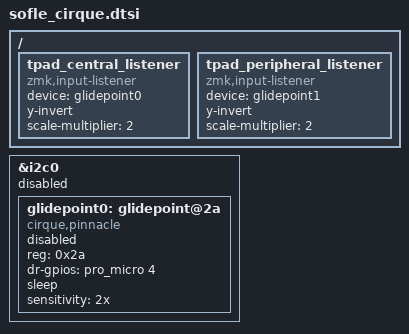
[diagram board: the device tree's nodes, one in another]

// Setup Cirque trackpad with i2c.
// Requires 3 pins; SCL, SDA and DR (data ready interrupt).

// Add #include "sofle_cirque.dtsi" to .overlay

&i2c0 {
    status = "disabled";
    glidepoint0: glidepoint@2a {
        compatible = "cirque,pinnacle";
        reg = <0x2a>;
        status = "disabled";
        dr-gpios = <&pro_micro 4 (GPIO_ACTIVE_HIGH)>;  // Assign pin for DR. Use pin 4 for Sofle RGB

        sleep;
        //no-taps;
        //rotate-90;
        sensitivity = "2x";
    };
};

/ {
	/* assign `input-listener` to all pointing devices */
	/* &glidepoint0 on central, &glidepoint1 on peripheral */

    tpad_central_listener {
        compatible = "zmk,input-listener";
        device = <&glidepoint0>;
        //xy-swap;
        y-invert;
        //x-invert;
        scale-multiplier = <2>;
	};

    tpad_peripheral_listener {
        compatible = "zmk,input-listener";
        device = <&glidepoint1>;
        //xy-swap;
        y-invert;
        //x-invert;
        scale-multiplier = <2>;
    };
};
